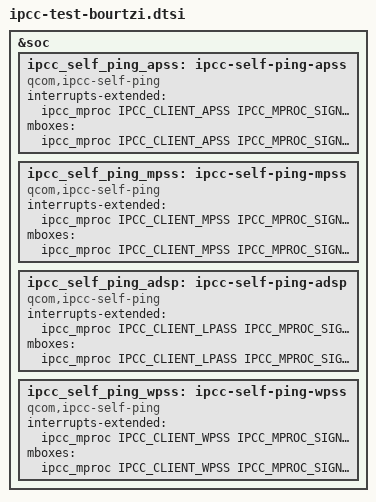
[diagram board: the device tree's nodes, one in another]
// SPDX-License-Identifier: BSD-3-Clause
/*
 * Copyright (c) Qualcomm Technologies, Inc. and/or its subsidiaries.
 */

#include <dt-bindings/soc/qcom,ipcc.h>
#include <dt-bindings/mailbox/qcom-ipcc.h>

&soc {
	ipcc_self_ping_apss: ipcc-self-ping-apss {
		compatible = "qcom,ipcc-self-ping";
		interrupts-extended = <&ipcc_mproc IPCC_CLIENT_APSS
			IPCC_MPROC_SIGNAL_SMP2P IRQ_TYPE_LEVEL_HIGH>;
		mboxes = <&ipcc_mproc IPCC_CLIENT_APSS IPCC_MPROC_SIGNAL_SMP2P>;
	};

	ipcc_self_ping_mpss: ipcc-self-ping-mpss {
		compatible = "qcom,ipcc-self-ping";
		interrupts-extended = <&ipcc_mproc IPCC_CLIENT_MPSS
				IPCC_MPROC_SIGNAL_PING IRQ_TYPE_LEVEL_HIGH>;
		mboxes = <&ipcc_mproc IPCC_CLIENT_MPSS IPCC_MPROC_SIGNAL_PING>;
	};

	ipcc_self_ping_adsp: ipcc-self-ping-adsp {
		compatible = "qcom,ipcc-self-ping";
		interrupts-extended = <&ipcc_mproc IPCC_CLIENT_LPASS
				IPCC_MPROC_SIGNAL_PING IRQ_TYPE_LEVEL_HIGH>;
		mboxes = <&ipcc_mproc IPCC_CLIENT_LPASS IPCC_MPROC_SIGNAL_PING>;
	};

	ipcc_self_ping_wpss: ipcc-self-ping-wpss {
		compatible = "qcom,ipcc-self-ping";
		interrupts-extended = <&ipcc_mproc IPCC_CLIENT_WPSS
				IPCC_MPROC_SIGNAL_PING IRQ_TYPE_LEVEL_HIGH>;
		mboxes = <&ipcc_mproc IPCC_CLIENT_WPSS IPCC_MPROC_SIGNAL_PING>;
	};
};
